# SAMA7G54D4G device description
Architecture: CORTEX-A7; Family: SAMA; Series: SAMA7G
Registers are 32-bit, read-write, reset 0x0 unless marked. A register's access mark holds for its fields unless they carry their own. Offsets are from the block's base; [hi:lo] are bit positions; {n}, {i} and the like mark numbered series; 'fields as' and 'values as' point back to an identical list.

## SHDWC — Shutdown Controller
Instances: SHDWC 0xE001D010
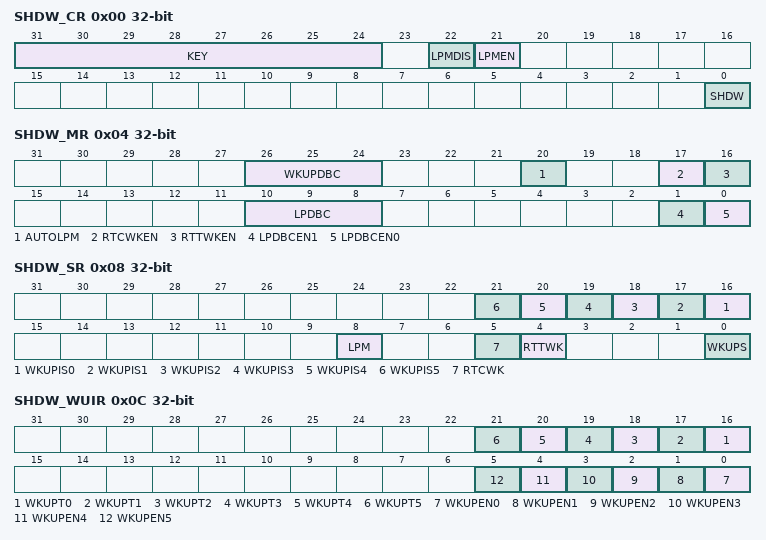
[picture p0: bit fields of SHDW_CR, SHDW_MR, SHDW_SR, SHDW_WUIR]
0x00 SHDW_CR wo reset not defined — Control Register
  [31:24] KEY — Password
    165=PASSWD (Writing any other value in this field aborts the write operation.)
  [22] LPMDIS — LPM Pad Disable
    0=No effect; 1=The LPM pad is set low (external regulator is set in standard powering state)
  [21] LPMEN — LPM Pad Enable
    0=No effect; 1=The LPM pad is set high (external regulator is set in special powering state)
  [0] SHDW — Shutdown Command
    0=No effect; 1=If KEY value is correct, asserts the SHDN pin
0x04 SHDW_MR — Mode Register
  [26:24] WKUPDBC — Wakeup Inputs Debouncer Period
    0=IMMEDIATE (Immediate, no debouncing, detected active at least on one SLCK edge.); 1=3_SLCK (PIOBUx shall be in its active state for at least 3 SLCK periods); 2=32_SLCK (PIOBUx shall be in its active state for at least 32 SLCK periods); 3=512_SLCK (PIOBUx shall be in its active state for at least 512 SLCK periods); 4=4096_SLCK (PIOBUx shall be in its active state for at least 4,096 SLCK periods); 5=32768_SLCK (PIOBUx shall be in its active state for at least 32,768 SLCK periods)
  [20] AUTOLPM — Automatic LPM Pad Management
    0=The LPM pad is never automatically modified by the RSTC; 1=The LPM pad is automatically modified by the RSTC when the system goes into or out of the ULP mode 2
  [17] RTCWKEN — Real-time Clock Wake-up Enable
    0=The RTC Alarm signal has no effect on the SHDWC; 1=The RTC Alarm signal forces the de-assertion of the SHDN pin
  [16] RTTWKEN — Real-time Timer Wake-up Enable
    0=The RTT Alarm signal has no effect on the SHDWC; 1=The RTT Alarm signal forces the de-assertion of the SHDN pin
  [10:8] LPDBC — Low-Power Debouncer Period
    0=DISABLE (Disables the low-power debouncers.); {v}={v+1}_RTCOUT (WKUP0/1 in active state for at least {v+1} RTCOUTx clock periods) (v=1..7)
  [1] LPDBCEN1 — Low-Power Debouncer Enable WKUPx
    0=NOT_ENABLE (The WKUPx input pin is not connected to the low-power debouncer.); 1=ENABLE (The WKUPx input pin is connected to the low-power debouncer and forces a system wakeup.)
  [0] LPDBCEN0 — Low-Power Debouncer Enable WKUPx
    values as LPDBCEN1
0x08 SHDW_SR ro — Status Register
  [n+16] WKUPIS{n} (n=0..5) — Wakeup 0 to 15 Input Status
    0=DISABLE (The corresponding wakeup input is disabled, or was inactive at the time the debouncer triggered a wakeup event.); 1=ENABLE (The corresponding wakeup input was active at the time the debouncer triggered a wakeup event.)
  [8] LPM — Low-Power Mode Pad Status
    0=The LPM pad is currently set to 0; 1=The LPM pad is currently set to 1
  [5] RTCWK — Real-time Clock Wake-up
    0=No wake-up alarm from the RTC occurred since the last read of SHDW_SR; 1=At least one wake-up alarm from the RTC occurred since the last read of SHDW_SR
  [4] RTTWK — Real-time Timer Wake-up
    0=No wake-up alarm from the RTT occurred since the last read of SHDW_SR; 1=At least one wake-up alarm from the RTT occurred since the last read of SHDW_SR
  [0] WKUPS — PIOBU, WKUP Wakeup Status
    0=NO (No wakeup due to the assertion of the PIOBU, WKUP pins has occurred since the last read of SHDW_SR.); 1=PRESENT (At least one wakeup due to the assertion of the PIOBU, WKUP pins has occurred since the last read of SHDW_SR.)
0x0C SHDW_WUIR — Wakeup Inputs Register
  [n+16] WKUPT{n} (n=0..5) — Wakeup 0 to 15 Input Type
    0=LOW (A falling edge followed by a low level on the corresponding wakeup input, for a period defined by WKUPDBC, forces wakeup of the core power supply.); 1=HIGH (A rising edge followed by a high level on the corresponding wakeup input, for a period defined by WKUPDBC, forces wakeup of the core power supply.)
  [n] WKUPEN{n} (n=0..5) — Wakeup 0 to 15 Input Enable
    0=DISABLE (The corresponding wakeup input has no wakeup effect.); 1=ENABLE (The corresponding wakeup input forces wakeup of the core power supply.)
